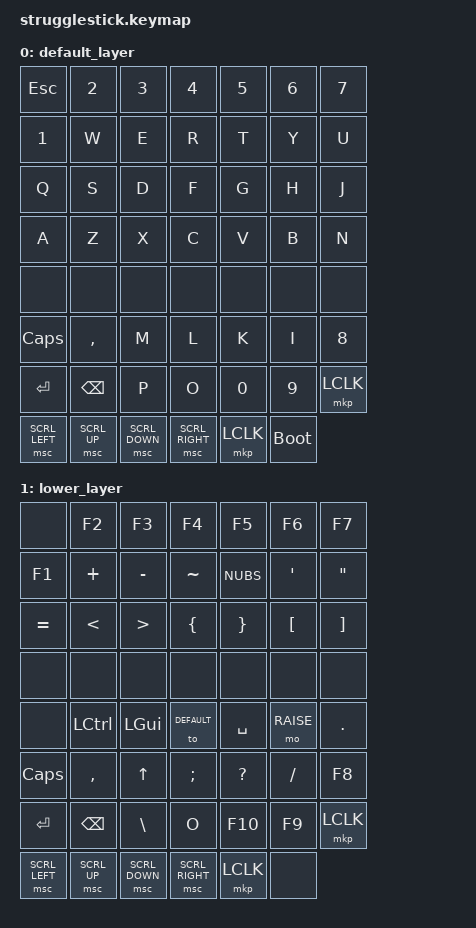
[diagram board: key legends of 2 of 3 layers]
/*
 * Copyright (c) 2020 The ZMK Contributors
/*
 * Copyright (c) 2020 The ZMK Contributors
 *
 * SPDX-License-Identifier: MIT
 */

#include <behaviors.dtsi>
#include <dt-bindings/zmk/keys.h>
#include <dt-bindings/zmk/bt.h>
#include <dt-bindings/zmk/pointing.h>

#define DEFAULT 0
#define LOWER   1
#define RAISE   2
#define ZMK_POINTING_DEFAULT_MOVE_VAL 1500  // default: 600
#define ZMK_POINTING_DEFAULT_SCRL_VAL 20    // default: 10

#include <dt-bindings/zmk/pointing.h>
/ {
    keymap0: keymap {
        compatible = "zmk,keymap";

        default_layer {
// -------------------------------------------------------------                   
// |  ESC   |  2    |  3  |  4  |   5  |   6   |  7   | 
// |   1    |  W    |  E  |  R  |   T  |   Y   |  U   | 
// |   Q    |  S    |  D  |  F  |   G  |   H   |  J   |  
// |   A    |  Z    |  X  |  C  |   V  |   B   |  N   |  
// |  SHFT  | LCTRL | WIN | MO  | SPACE| RALT  | DOT  |
// |  CAPS  |  ,    |  M  |  L  |   K  |   I   |  8   | 
// |  ENTER |  BACK |  P  |  O  |   0  |   9   | LCLK |
// |   ←    |   ↑   |  ↓  |  →  |  NO  | POWER |  
// --------------------------------------------------------------
            bindings = <
                &kp ESC          &kp N2        &kp N3          &kp N4            &kp N5        &kp N6        &kp N7        
                &kp N1           &kp W         &kp E           &kp R             &kp T         &kp Y         &kp U         
                &kp Q            &kp S         &kp D           &kp F             &kp G         &kp H         &kp J         
                &kp A            &kp Z         &kp X           &kp C             &kp V         &kp B         &kp N         
                &none         &none          &none          &none          &none          &none         &none       
                &kp CAPS         &kp COMMA     &kp M           &kp L             &kp K         &kp I         &kp N8        
                &kp RET          &kp BSPC      &kp P           &kp O             &kp N0        &kp N9        &mkp LCLK     
                &msc SCRL_LEFT   &msc SCRL_UP  &msc SCRL_DOWN  &msc SCRL_RIGHT   &mkp LCLK     &bootloader
            >;
        };

        lower_layer {
            bindings = <
                &none        &kp F2        &kp F3        &kp F4        &kp F5        &kp F6       &kp F7        
                &kp F1        &kp PLUS      &kp MINUS     &kp TILDE     &kp NUBS      &kp SQT       &kp DQT       
                &kp EQUAL     &kp LT        &kp GT        &kp LBRC      &kp RBRC      &kp LBKT      &kp RBKT      
               &none         &none          &none          &none          &none          &none         &none       
                &none         &kp LCTRL     &kp LGUI      &to DEFAULT         &kp SPACE     &mo RAISE        &kp DOT      
                &kp CAPS      &kp COMMA     &kp UP        &kp SEMI      &kp QMARK     &kp FSLH      &kp F8        
                &kp RET       &kp BSPC      &kp BSLH      &kp O         &kp F10       &kp F9        &mkp LCLK     
                &msc SCRL_LEFT   &msc SCRL_UP  &msc SCRL_DOWN  &msc SCRL_RIGHT        &mkp LCLK      &none
            >;
        };

        raise_layer {
            bindings = <
                &none         &bt BT_SEL 1   &bt BT_SEL 2   &bt BT_SEL 3   &bt BT_SEL 4   &none         &none         
                &bt BT_SEL 0  &none          &none          &none          &none          &none         &none         
                &none         &none          &none          &none          &none          &none         &none         
                &none         &none          &none          &none          &none          &none         &none         
                &none         &none          &none          &none          &none          &none         &none         
                &none         &none          &none          &none          &none          &none         &none         
                &none         &none          &none          &none          &bootloader    &bt BT_CLR    &none         
                &none         &none          &none          &none          &none          &mkp LCLK     &none         
            >;
        };
    };
};
